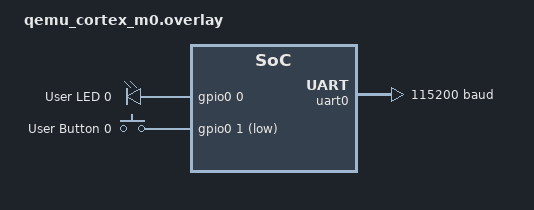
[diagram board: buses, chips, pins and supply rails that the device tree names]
/**
 * Copyright (c) 2026
 * SPDX-License-Identifier: GPL-3.0
 *
 * qemu_cortex_m0 设备树覆盖（QEMU 仿真）
 * Note: ARM Cortex-M0, nRF51 based
 */

#include <zephyr/dt-bindings/gpio/gpio.h>

/ {
	aliases {
		led0 = &led0;
		sw0  = &button0;
	};

	leds {
		compatible = "gpio-leds";
		led0: led_0 {
			gpios = <&gpio0 0 GPIO_ACTIVE_HIGH>;
			label = "User LED 0";
		};
	};

	buttons {
		compatible = "gpio-keys";
		button0: button_0 {
			gpios = <&gpio0 1 GPIO_ACTIVE_LOW>;
			label = "User Button 0";
		};
	};
};

&uart0 {
	status = "okay";
	current-speed = <115200>;
};

&gpio0 {
	status = "okay";
};

/* Expand SRAM for QEMU simulation */
&sram0 {
	reg = <0x20000000 0x80000>;
};
